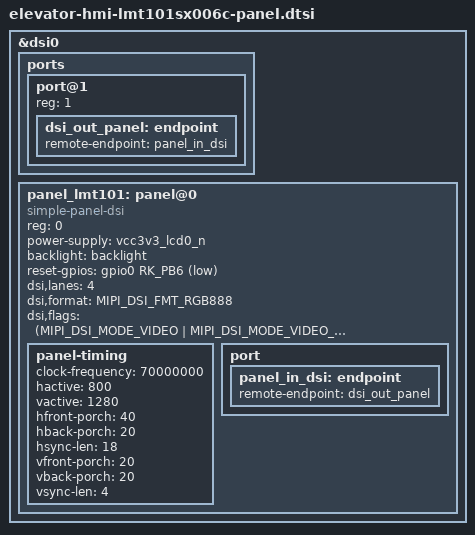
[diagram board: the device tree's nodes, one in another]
// SPDX-License-Identifier: (GPL-2.0 OR MIT)
/*
 * LMT101SX006C on RK3566 MIPI-DSI0 — TASK-122: `simple-panel-dsi` bring-up probe.
 *
 * Uses generic panel-simple DSI path (Sleep Out / Display On DCS only) instead of
 * `jadard,jd9365da-h3` + `elevator-hmi,lmt101sx006c`.
 *
 * Replaces the stock EVB `simple-panel-dsi` `panel@0` under &dsi0 from
 * rk3568-evb.dtsi (same graph pattern: panel endpoint + &dsi0/ports/port@1).
 *
 * Phandles: vcc3v3_lcd0_n, backlight (rk3568-evb.dtsi / board overlay).
 *
 * TASK-121: reset-gpios on gpio0 RK_PB6 (`gt1x` disabled in board DTS).
 *
 * Regression: revert `compatible`, supplies, and jadard properties to restore product panel.
 */

#include <dt-bindings/display/drm_mipi_dsi.h>
#include <dt-bindings/gpio/gpio.h>
#include <dt-bindings/pinctrl/rockchip.h>

&dsi0 {
	/delete-node/ panel@0;

	ports {
		/delete-node/ port@1;

		port@1 {
			reg = <1>;
			dsi_out_panel: endpoint {
				remote-endpoint = <&panel_in_dsi>;
			};
		};
	};

	panel_lmt101: panel@0 {
		compatible = "simple-panel-dsi";
		reg = <0>;
		power-supply = <&vcc3v3_lcd0_n>;
		backlight = <&backlight>;
		reset-gpios = <&gpio0 RK_PB6 GPIO_ACTIVE_LOW>;

		dsi,lanes = <4>;
		dsi,format = <MIPI_DSI_FMT_RGB888>;
		/*
		 * Match `panel-jadard-jd9365da-h3` video flags (DSI host burst + no HS EoT).
		 */
		dsi,flags = <(MIPI_DSI_MODE_VIDEO | MIPI_DSI_MODE_VIDEO_BURST | MIPI_DSI_MODE_EOT_PACKET)>;

		panel-timing {
			clock-frequency = <70000000>;
			hactive = <800>;
			vactive = <1280>;
			hfront-porch = <40>;
			hback-porch = <20>;
			hsync-len = <18>;
			vfront-porch = <20>;
			vback-porch = <20>;
			vsync-len = <4>;
		};

		port {
			panel_in_dsi: endpoint {
				remote-endpoint = <&dsi_out_panel>;
			};
		};
	};
};
